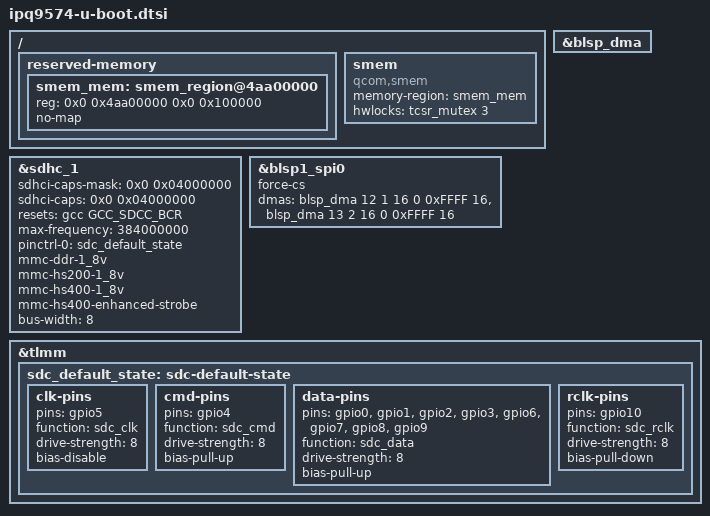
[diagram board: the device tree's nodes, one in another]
// SPDX-License-Identifier: GPL-2.0+
/*
 * Copyright (c) Qualcomm Technologies, Inc. and/or its subsidiaries.
 */

/ {

	reserved-memory {

		/delete-node/ smem;
		smem_mem: smem_region@4aa00000 {
			reg = <0x0 0x4aa00000 0x0 0x100000>;
			no-map;
		};
	};

	smem {
		compatible = "qcom,smem";
		memory-region = <&smem_mem>;
		hwlocks = <&tcsr_mutex 3>;
	};
};

&sdhc_1 {
	sdhci-caps-mask = <0x0 0x04000000>;
	sdhci-caps = <0x0 0x04000000>;
	resets = <&gcc GCC_SDCC_BCR>;
	reset-names = "bcr_rst";
	max-frequency = <96000000>;
	pinctrl-0 = <&sdc_default_state>;
	pinctrl-names = "default";
	mmc-ddr-1_8v;
	mmc-hs200-1_8v;
	mmc-hs400-1_8v;
	mmc-hs400-enhanced-strobe;
	max-frequency = <384000000>;
	bus-width = <8>;
	status = "okay";
};

&blsp1_spi0 {
	force-cs;
	dmas = <&blsp_dma 12 1 16 0 0xFFFF 16>,
	       <&blsp_dma 13 2 16 0 0xFFFF 16>;
	status = "okay";
};

&blsp_dma {
	#dma-cells = <6>;
	status = "okay";
};

&tlmm {
	sdc_default_state: sdc-default-state {
		clk-pins {
			pins = "gpio5";
			function = "sdc_clk";
			drive-strength = <8>;
			bias-disable;
		};

		cmd-pins {
			pins = "gpio4";
			function = "sdc_cmd";
			drive-strength = <8>;
			bias-pull-up;
		};

		data-pins {
			pins = "gpio0", "gpio1", "gpio2",
			       "gpio3", "gpio6", "gpio7",
			       "gpio8", "gpio9";
			function = "sdc_data";
			drive-strength = <8>;
			bias-pull-up;
		};

		rclk-pins {
			pins = "gpio10";
			function = "sdc_rclk";
			drive-strength = <8>;
			bias-pull-down;
		};
	};
};
